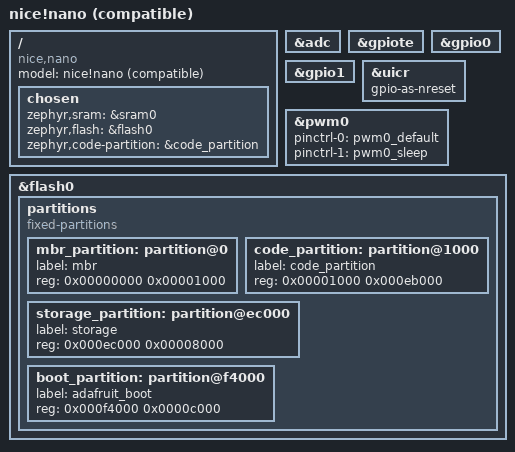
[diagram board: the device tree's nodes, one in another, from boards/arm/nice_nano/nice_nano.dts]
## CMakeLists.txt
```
cmake_minimum_required(VERSION 3.20.0)

# Pick up the local board definition under boards/arm/nice_nano/
list(APPEND BOARD_ROOT ${CMAKE_CURRENT_SOURCE_DIR})

find_package(Zephyr REQUIRED HINTS $ENV{ZEPHYR_BASE})
project(irtransmitter)

target_sources(app PRIVATE
    src/main.c
    src/ir.c
    src/ir_rx.c
    src/crashlog.c
)

target_include_directories(app PRIVATE src)
```

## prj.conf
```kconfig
# BLE peripheral with Nordic UART Service
# Off while learning codes: the capture ISR polls the pin with IRQs masked.
CONFIG_BT=n
#CONFIG_BT_PERIPHERAL=y
#CONFIG_BT_DEVICE_NAME="IR-Tx"
#CONFIG_BT_MAX_CONN=1
#CONFIG_BT_NUS=y

# Larger MTU so a long IR code fits in one BLE write
#CONFIG_BT_BUF_ACL_RX_SIZE=251
#CONFIG_BT_BUF_ACL_TX_SIZE=251
#CONFIG_BT_L2CAP_TX_MTU=247

# IR carrier hardware
CONFIG_PWM=y
CONFIG_GPIO=y

# USB CDC ACM serial = console + logs + command input (no J-Link needed)
CONFIG_USB_DEVICE_STACK=y
CONFIG_USB_DEVICE_PRODUCT="IR-Tx"
CONFIG_USB_DEVICE_INITIALIZE_AT_BOOT=n
CONFIG_SERIAL=y
CONFIG_UART_INTERRUPT_DRIVEN=y
CONFIG_UART_LINE_CTRL=y
CONFIG_CONSOLE=y
CONFIG_UART_CONSOLE=y

# No logging subsystem: its thread would be another concurrent writer on
# the CDC ACM TX ring buffer. Everything goes through printk on main.
CONFIG_LOG=n
CONFIG_USB_CDC_ACM_RINGBUF_SIZE=4096

# Memory
CONFIG_HEAP_MEM_POOL_SIZE=2048
CONFIG_MAIN_STACK_SIZE=2048

CONFIG_ASSERT=y

# Thread names for the crash log
CONFIG_THREAD_NAME=y
# Our own fatal handler (src/crashlog.c) replaces NCS's
CONFIG_RESET_ON_FATAL_ERROR=n
```

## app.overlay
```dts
/* USB CDC ACM serial port as the console. */
/ {
	chosen {
		zephyr,console = &cdc_acm_uart0;
	};
};

&usbd {
	status = "okay";
	cdc_acm_uart0: cdc_acm_uart0 {
		compatible = "zephyr,cdc-acm-uart";
	};
};
```

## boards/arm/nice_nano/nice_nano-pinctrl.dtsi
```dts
&pinctrl {
	/* IR carrier: PWM0 channel 0 -> P0.31 (DAT of the IR transmitter module). */
	pwm0_default: pwm0_default {
		group1 {
			psels = <NRF_PSEL(PWM_OUT0, 0, 31)>;
			/* The module has no transistor: DAT drives the IR LED directly. */
			nordic,drive-mode = <NRF_DRIVE_H0H1>;
		};
	};

	pwm0_sleep: pwm0_sleep {
		group1 {
			psels = <NRF_PSEL(PWM_OUT0, 0, 31)>;
			low-power-enable;
		};
	};
};
```

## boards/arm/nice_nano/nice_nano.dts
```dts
/dts-v1/;
#include <nordic/nrf52840_qiaa.dtsi>
#include "nice_nano-pinctrl.dtsi"

/ {
	model = "nice!nano (compatible)";
	compatible = "nice,nano";

	chosen {
		zephyr,sram = &sram0;
		zephyr,flash = &flash0;
		zephyr,code-partition = &code_partition;
	};
};

&adc {
	status = "okay";
};

&gpiote {
	status = "okay";
};

&gpio0 {
	status = "okay";
};

&gpio1 {
	status = "okay";
};

&uicr {
	gpio-as-nreset;
};

&pwm0 {
	status = "okay";
	pinctrl-0 = <&pwm0_default>;
	pinctrl-1 = <&pwm0_sleep>;
	pinctrl-names = "default", "sleep";
};

&flash0 {
	/*
	 * Layout for the Adafruit nRF52 bootloader with NO SoftDevice
	 * (INFO_UF2.TXT: "SoftDevice: not found"): the bootloader then jumps
	 * to MBR_SIZE = 0x1000. Bootloader occupies the last 48 KB of flash.
	 */
	partitions {
		compatible = "fixed-partitions";
		#address-cells = <1>;
		#size-cells = <1>;

		mbr_partition: partition@0 {
			label = "mbr";
			reg = <0x00000000 0x00001000>;
		};

		code_partition: partition@1000 {
			label = "code_partition";
			reg = <0x00001000 0x000eb000>;
		};

		storage_partition: partition@ec000 {
			label = "storage";
			reg = <0x000ec000 0x00008000>;
		};

		boot_partition: partition@f4000 {
			label = "adafruit_boot";
			reg = <0x000f4000 0x0000c000>;
		};
	};
};
```

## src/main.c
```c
#include <stdio.h>
#include <stdlib.h>
#include <string.h>

#include <soc.h>
#include <zephyr/kernel.h>
#include <zephyr/sys/printk.h>
#include <zephyr/logging/log.h>
#include <zephyr/drivers/uart.h>
#include <zephyr/drivers/pwm.h>
#include <zephyr/drivers/gpio.h>
#include <zephyr/dt-bindings/gpio/nordic-nrf-gpio.h>
#include <zephyr/usb/usb_device.h>
#if defined(CONFIG_BT)
#include <zephyr/bluetooth/bluetooth.h>
#include <zephyr/bluetooth/conn.h>
#include <zephyr/bluetooth/uuid.h>
#include <bluetooth/services/nus.h>
#endif

#include "ir.h"
#include "ir_rx.h"

void crashlog_boot(void);
void crashlog_report(void);

LOG_MODULE_REGISTER(main, LOG_LEVEL_INF);

#define LINE_BUF_SIZE 4096
#define MAX_PULSES    1024

/* Shortest frame worth reporting (leader + a few bits). */
#define MIN_FRAME_DURATIONS 8

/*
 * nice!nano switched VCC pin (feeds the IR transmitter module): P0.13
 * drives the switch. Active low on v2, active high on v1; EXTVCC overrides.
 */
#define EXT_VCC_PIN     13
#define EXT_VCC_ON_LEVEL 0

/* Samsung32 timings (us) and the TV's address byte. */
#define SAMSUNG_ADDR    0x07
#define SAMSUNG_HDR     4500
#define SAMSUNG_BIT     560
#define SAMSUNG_ONE     1690
#define SAMSUNG_ZERO    560
#define SAMSUNG_GAP     46000

/* Adafruit nRF52 bootloader: GPREGRET magic that reboots into UF2 mode. */
#define DFU_MAGIC_UF2_RESET 0x57

typedef void (*reply_fn)(const char *msg);

static uint16_t pulse_buf[MAX_PULSES];

/* Last captured frame, replayed by REPLAY. */
static uint16_t last_rx[IR_RX_MAX_PULSES];
static size_t   last_rx_len;

/* Commands arrive from both USB console and BLE NUS threads. */
static K_MUTEX_DEFINE(cmd_lock);

#if defined(CONFIG_BT)
static char     line_buf[LINE_BUF_SIZE];
static size_t   line_len;

static struct bt_conn *current_conn;

static const struct bt_data ad[] = {
	BT_DATA_BYTES(BT_DATA_FLAGS, (BT_LE_AD_GENERAL | BT_LE_AD_NO_BREDR)),
	BT_DATA(BT_DATA_NAME_COMPLETE, CONFIG_BT_DEVICE_NAME,
		sizeof(CONFIG_BT_DEVICE_NAME) - 1),
};

static const struct bt_data sd[] = {
	BT_DATA_BYTES(BT_DATA_UUID128_ALL, BT_UUID_NUS_VAL),
};

static void nus_reply(const char *msg)
{
	if (!current_conn) {
		return;
	}
	int err = bt_nus_send(current_conn, (const uint8_t *)msg, strlen(msg));
	if (err) {
		LOG_WRN("nus send failed: %d", err);
	}
}

#endif /* CONFIG_BT */

static void usb_reply(const char *msg)
{
	printk("%s", msg);
}

static void send_and_reply(uint32_t carrier_hz, const uint16_t *d, size_t n,
			   reply_fn reply)
{
	int err = ir_send_raw(carrier_hz, d, n);
	if (err) {
		char buf[32];
		snprintf(buf, sizeof(buf), "ERR send %d\n", err);
		reply(buf);
	} else {
		reply("OK\n");
	}
}

/* Samsung32: addr, addr, cmd, ~cmd, LSB first, then a stop bit. Returns durations. */
static size_t samsung_frame(uint8_t cmd, uint16_t *d)
{
	uint32_t v = SAMSUNG_ADDR | (SAMSUNG_ADDR << 8) | ((uint32_t)cmd << 16) |
		     ((uint32_t)(uint8_t)~cmd << 24);
	size_t n = 0;

	d[n++] = SAMSUNG_HDR;
	d[n++] = SAMSUNG_HDR;
	for (int i = 0; i < 32; i++) {
		d[n++] = SAMSUNG_BIT;
		d[n++] = (v & BIT(i)) ? SAMSUNG_ONE : SAMSUNG_ZERO;
	}
	d[n++] = SAMSUNG_BIT;
	d[n++] = SAMSUNG_GAP;
	return n;
}

static void print_frame(const uint16_t *d, size_t n, bool raw);

/*
 * Connect the input buffer (with pull-up, so idle pins stay high) on every
 * pin not used by the firmware, so pin scans can see a stray wire.
 * Returns the mask of P0 pins that were left alone.
 */
static uint32_t scan_inputs_enable(void)
{
	/* Skip: P0.13 ext VCC, P0.15 LED, P0.17 RX power, P0.18 reset, P0.20 RX, P0.31 IR TX. */
	const uint32_t skip0 = BIT(13) | BIT(15) | BIT(17) | BIT(18) | BIT(20) | BIT(31);

	for (int p = 0; p < 48; p++) {
		if (p < 32 && (skip0 & BIT(p))) {
			continue;
		}
		volatile uint32_t *cnf = p < 32 ? &NRF_P0->PIN_CNF[p] : &NRF_P1->PIN_CNF[p - 32];

		*cnf = GPIO_PIN_CNF_DIR_Input << GPIO_PIN_CNF_DIR_Pos |
		       GPIO_PIN_CNF_INPUT_Connect << GPIO_PIN_CNF_INPUT_Pos |
		       GPIO_PIN_CNF_PULL_Pullup << GPIO_PIN_CNF_PULL_Pos;
	}
	k_msleep(5);
	return skip0 & ~BIT(20);
}

/* IR LED pin, for the bit-banged carrier diagnostic (PWM must be idle). */
#define IR_TX_PIN 31

/* Bit-banged 38 kHz carrier at 1/3 duty, sampling our receiver meanwhile. */
static void bitbang_send(const uint16_t *d, size_t n)
{
	const uint32_t cpu = SystemCoreClock / 1000000U;
	const uint32_t period = SystemCoreClock / 38000U;
	const uint32_t high = period / 3U;

	for (size_t i = 0; i < n; i++) {
		uint32_t start = DWT->CYCCNT;
		uint32_t span = d[i] * cpu;
		bool mark = (i & 1U) == 0U;

		while (DWT->CYCCNT - start < span) {
			if (mark && (DWT->CYCCNT - start) % period < high) {
				NRF_P0->OUTSET = BIT(IR_TX_PIN);
			} else {
				NRF_P0->OUTCLR = BIT(IR_TX_PIN);
			}
			ir_rx_loopback_sample();
		}
	}
	NRF_P0->OUTCLR = BIT(IR_TX_PIN);
}

static void process_line(char *line, reply_fn reply)
{
	char *saveptr = NULL;
	char *cmd = strtok_r(line, " ", &saveptr);
	if (!cmd) {
		reply("ERR empty\n");
		return;
	}

	if (strcmp(cmd, "TX") == 0) {
		char *khz_str = strtok_r(NULL, " ", &saveptr);
		if (!khz_str) {
			reply("ERR no_khz\n");
			return;
		}
		int khz = atoi(khz_str);
		if (khz < 20 || khz > 60) {
			reply("ERR bad_khz\n");
			return;
		}

		size_t n = 0;
		char *tok;
		while ((tok = strtok_r(NULL, " ", &saveptr)) != NULL) {
			if (n >= MAX_PULSES) {
				reply("ERR too_many\n");
				return;
			}
			int v = atoi(tok);
			if (v <= 0 || v > 65535) {
				reply("ERR bad_pulse\n");
				return;
			}
			pulse_buf[n++] = (uint16_t)v;
		}
		if (n < 2) {
			reply("ERR no_pulses\n");
			return;
		}
		if (n & 1U) {
			reply("ERR odd_pulses\n");
			return;
		}

		send_and_reply((uint32_t)khz * 1000U, pulse_buf, n, reply);
	} else if (strcmp(cmd, "REPLAY") == 0) {
		char *khz_str = strtok_r(NULL, " ", &saveptr);
		int khz = khz_str ? atoi(khz_str) : 38;

		if (last_rx_len < 2) {
			reply("ERR nothing_captured\n");
			return;
		}
		send_and_reply((uint32_t)khz * 1000U, last_rx, last_rx_len, reply);
	} else if (strcmp(cmd, "SAMSUNG") == 0) {
		char *arg = strtok_r(NULL, " ", &saveptr);
		char *rep = strtok_r(NULL, " ", &saveptr);
		int times = rep ? atoi(rep) : 1;

		if (!arg) {
			reply("ERR no_cmd\n");
			return;
		}
		size_t n = samsung_frame((uint8_t)strtoul(arg, NULL, 0), pulse_buf);
		for (int i = 0; i < times; i++) {
			int err = ir_send_raw(38000U, pulse_buf, n);
			if (err) {
				char buf[32];
				snprintf(buf, sizeof(buf), "ERR send %d\n", err);
				reply(buf);
				return;
			}
		}
		reply("OK\n");
	} else if (strcmp(cmd, "LOOP") == 0) {
		/* Send a Samsung frame and decode what our own receiver saw. */
		static uint16_t rx[IR_RX_MAX_PULSES];
		char *arg = strtok_r(NULL, " ", &saveptr);
		bool raw;

		if (!arg) {
			reply("ERR no_cmd\n");
			return;
		}
		size_t n = samsung_frame((uint8_t)strtoul(arg, NULL, 0), pulse_buf);

		ir_rx_loopback_begin();
		int err = ir_send_raw_ex(38000U, pulse_buf, n, ir_rx_loopback_wait_us);
		size_t got = ir_rx_loopback_end(rx, ARRAY_SIZE(rx), &raw);

		if (err) {
			reply("ERR send\n");
		} else if (got == 0) {
			reply("LOOP nothing received\n");
		} else {
			print_frame(rx, got, raw);
		}
	} else if (strcmp(cmd, "LOOPBB") == 0) {
		/* Like LOOP but with a CPU bit-banged carrier: isolates the PWM. */
		static uint16_t rx[IR_RX_MAX_PULSES];
		char *arg = strtok_r(NULL, " ", &saveptr);
		bool raw;

		if (!arg) {
			reply("ERR no_cmd\n");
			return;
		}
		size_t n = samsung_frame((uint8_t)strtoul(arg, NULL, 0), pulse_buf);

		NRF_P0->PIN_CNF[IR_TX_PIN] = GPIO_PIN_CNF_DIR_Output << GPIO_PIN_CNF_DIR_Pos |
					     GPIO_PIN_CNF_INPUT_Disconnect << GPIO_PIN_CNF_INPUT_Pos |
					     GPIO_PIN_CNF_DRIVE_H0H1 << GPIO_PIN_CNF_DRIVE_Pos;
		/* An enabled PWM owns its PSEL pin and would override the GPIO. */
		uint32_t pwm_en = NRF_PWM0->ENABLE;

		NRF_PWM0->ENABLE = 0;
		ir_rx_loopback_begin();
		unsigned int key = irq_lock();
		bitbang_send(pulse_buf, n);
		irq_unlock(key);
		NRF_PWM0->ENABLE = pwm_en;
		size_t got = ir_rx_loopback_end(rx, ARRAY_SIZE(rx), &raw);

		if (got == 0) {
			reply("LOOPBB nothing received\n");
		} else {
			print_frame(rx, got, raw);
		}
	} else if (strcmp(cmd, "TXSCAN") == 0) {
		/* Transmit a Samsung frame while counting transitions on every pin. */
		static uint32_t changes[48];
		static uint32_t prev0, prev1;
		char *arg = strtok_r(NULL, " ", &saveptr);
		size_t n = samsung_frame(arg ? (uint8_t)strtoul(arg, NULL, 0) : 0x07, pulse_buf);
		const uint32_t cpu = SystemCoreClock / 1000000U;

		memset(changes, 0, sizeof(changes));
		scan_inputs_enable();
		gpio_pin_interrupt_configure(DEVICE_DT_GET(DT_NODELABEL(gpio0)), 20, GPIO_INT_DISABLE);
		prev0 = NRF_P0->IN;
		prev1 = NRF_P1->IN;

		uint32_t period_ns = 1000000000U / 38000U;
		const struct device *pwm = DEVICE_DT_GET(DT_NODELABEL(pwm0));

		for (size_t i = 0; i <= n; i++) {
			/* One extra round after the frame: listen for the receiver's tail. */
			uint32_t dur = i < n ? pulse_buf[i] : 20000U;
			bool mark = i < n && (i & 1U) == 0U;

			pwm_set(pwm, 0, period_ns, mark ? period_ns / 3U : 0U, 0);
			uint32_t start = DWT->CYCCNT;

			while (DWT->CYCCNT - start < dur * cpu) {
				uint32_t in0 = NRF_P0->IN, in1 = NRF_P1->IN;
				uint32_t d0 = (in0 ^ prev0) & ~BIT(31), d1 = in1 ^ prev1;

				while (d0) {
					changes[__builtin_ctz(d0)]++;
					d0 &= d0 - 1;
				}
				while (d1) {
					changes[32 + __builtin_ctz(d1)]++;
					d1 &= d1 - 1;
				}
				prev0 = in0;
				prev1 = in1;
			}
		}
		gpio_pin_interrupt_configure(DEVICE_DT_GET(DT_NODELABEL(gpio0)), 20, GPIO_INT_EDGE_FALLING);

		printk("TXSCAN P0.IN=0x%08X P1.IN=0x%08X changes:", prev0, prev1);
		for (int p = 0; p < 48; p++) {
			if (changes[p]) {
				printk(" P%d.%02d=%u", p / 32, p % 32, changes[p]);
			}
		}
		printk(" (end)\n");
	} else if (strcmp(cmd, "SCAN") == 0) {
		/*
		 * Find which pin a signal actually arrives on: connect the input
		 * buffer (with pull-up, so idle pins stay high) on every free pin,
		 * poll both ports and count transitions per pin.
		 */
		char *arg = strtok_r(NULL, " ", &saveptr);
		uint32_t secs = arg ? strtoul(arg, NULL, 0) : 15;
		static uint32_t changes[48];
		const uint32_t skip0 = scan_inputs_enable();

		memset(changes, 0, sizeof(changes));

		printk("SCAN %us: press the remote now\n", secs);
		uint32_t prev0 = NRF_P0->IN, prev1 = NRF_P1->IN;
		int64_t end = k_uptime_get() + secs * 1000;

		while (k_uptime_get() < end) {
			uint32_t in0 = NRF_P0->IN, in1 = NRF_P1->IN;
			uint32_t d0 = (in0 ^ prev0) & ~skip0, d1 = in1 ^ prev1;

			while (d0) {
				int b = __builtin_ctz(d0);
				changes[b]++;
				d0 &= d0 - 1;
			}
			while (d1) {
				int b = __builtin_ctz(d1);
				changes[32 + b]++;
				d1 &= d1 - 1;
			}
			prev0 = in0;
			prev1 = in1;
		}

		printk("SCAN result:");
		for (int p = 0; p < 48; p++) {
			if (changes[p]) {
				printk(" P%d.%02d=%u", p / 32, p % 32, changes[p]);
			}
		}
		printk(" (end)\n");
	} else if (strcmp(cmd, "PROBE") == 0) {
		char buf[48];

		snprintf(buf, sizeof(buf), "PROBE out_with_pulldown=%d\n", ir_rx_probe());
		reply(buf);
	} else if (strcmp(cmd, "REGS") == 0) {
		char buf[160];

		snprintf(buf, sizeof(buf),
			 "REGS PWM0.ENABLE=%u PWM0.PSEL0=0x%08X PIN_CNF31=0x%08X OUT31=%u P0.13=%u\n",
			 NRF_PWM0->ENABLE, NRF_PWM0->PSEL.OUT[0], NRF_P0->PIN_CNF[IR_TX_PIN],
			 (NRF_P0->OUT >> IR_TX_PIN) & 1U, (NRF_P0->OUT >> 13) & 1U);
		reply(buf);
	} else if (strcmp(cmd, "PINTEST") == 0) {
		/*
		 * Drive P0.31 as plain GPIO (PWM released) and read back the real
		 * pin level through the input buffer: catches shorts, and blinks
		 * the module's LED without relying on the PWM driver.
		 */
		char *arg = strtok_r(NULL, " ", &saveptr);
		int times = arg ? atoi(arg) : 5;
		uint32_t pwm_en = NRF_PWM0->ENABLE;
		char buf[64];

		NRF_PWM0->ENABLE = 0;
		NRF_P0->PIN_CNF[IR_TX_PIN] = GPIO_PIN_CNF_DIR_Output << GPIO_PIN_CNF_DIR_Pos |
					     GPIO_PIN_CNF_INPUT_Connect << GPIO_PIN_CNF_INPUT_Pos |
					     GPIO_PIN_CNF_DRIVE_H0H1 << GPIO_PIN_CNF_DRIVE_Pos;
		for (int i = 0; i < times; i++) {
			NRF_P0->OUTSET = BIT(IR_TX_PIN);
			k_msleep(1000);
			int hi = (NRF_P0->IN >> IR_TX_PIN) & 1U;
			NRF_P0->OUTCLR = BIT(IR_TX_PIN);
			k_msleep(1000);
			int lo = (NRF_P0->IN >> IR_TX_PIN) & 1U;

			snprintf(buf, sizeof(buf), "PINTEST %d: wrote 1 read %d, wrote 0 read %d\n",
				 i + 1, hi, lo);
			reply(buf);
		}
		NRF_PWM0->ENABLE = pwm_en;
	} else if (strcmp(cmd, "SLOWBLINK") == 0) {
		char *arg = strtok_r(NULL, " ", &saveptr);
		int times = arg ? atoi(arg) : 10;

		for (int i = 0; i < times; i++) {
			ir_level(true);
			k_msleep(1000);
			ir_level(false);
			k_msleep(1000);
		}
		reply("OK\n");
	} else if (strcmp(cmd, "BLINK") == 0) {
		/* Visible through a phone camera: 5 x 0.5 s bursts of carrier. */
		ir_pulse(500, 500, 5);
		reply("OK\n");
	} else if (strcmp(cmd, "PWR29") == 0) {
		/* Power the transmitter module from P0.29 (high drive) instead of VCC. */
		char *arg = strtok_r(NULL, " ", &saveptr);
		int on = arg ? atoi(arg) : 1;

		gpio_pin_configure(DEVICE_DT_GET(DT_NODELABEL(gpio0)), 29,
				   (on ? GPIO_OUTPUT_HIGH : GPIO_OUTPUT_LOW) | NRF_GPIO_DRIVE_H0H1);
		reply("OK\n");
	} else if (strcmp(cmd, "INV") == 0) {
		char *arg = strtok_r(NULL, " ", &saveptr);

		ir_set_inverted(arg && atoi(arg));
		reply("OK\n");
	} else if (strcmp(cmd, "EXTVCC") == 0) {
		char *arg = strtok_r(NULL, " ", &saveptr);
		int on = arg ? atoi(arg) : 1;

		gpio_pin_set_raw(DEVICE_DT_GET(DT_NODELABEL(gpio0)), EXT_VCC_PIN,
				 on ? EXT_VCC_ON_LEVEL : !EXT_VCC_ON_LEVEL);
		reply("OK\n");
	} else if (strcmp(cmd, "STAT") == 0) {
		int pwr, out;
		uint32_t edges;
		char buf[64];

		ir_rx_stat(&pwr, &out, &edges);
		snprintf(buf, sizeof(buf), "STAT pwr=%d out=%d edges=%u\n", pwr, out, edges);
		reply(buf);
	} else if (strcmp(cmd, "CRASH") == 0) {
		crashlog_report();
	} else if (strcmp(cmd, "DUMP") == 0) {
		const uint16_t *iv;
		size_t n = ir_rx_last_raw(&iv);

		printk("DUMP %u", (unsigned)n);
		for (size_t i = 0; i < n; i++) {
			printk(" %u", iv[i]);
		}
		printk("\n");
	} else if (strcmp(cmd, "DFU") == 0) {
		reply("OK rebooting to UF2 bootloader\n");
		k_msleep(100);
		NRF_POWER->GPREGRET = DFU_MAGIC_UF2_RESET;
		NVIC_SystemReset();
	} else {
		reply("ERR unknown\n");
	}
}

#if defined(CONFIG_BT)
static void nus_received(struct bt_conn *conn, const uint8_t *const data,
			 uint16_t len)
{
	ARG_UNUSED(conn);

	for (uint16_t i = 0; i < len; i++) {
		char c = (char)data[i];
		if (c == '\n' || c == '\r') {
			if (line_len > 0) {
				line_buf[line_len] = '\0';
				k_mutex_lock(&cmd_lock, K_FOREVER);
				process_line(line_buf, nus_reply);
				k_mutex_unlock(&cmd_lock);
				line_len = 0;
			}
		} else if (line_len < LINE_BUF_SIZE - 1) {
			line_buf[line_len++] = c;
		} else {
			line_len = 0;
			nus_reply("ERR overflow\n");
		}
	}
}

static struct bt_nus_cb nus_cb = {
	.received = nus_received,
};

static void connected(struct bt_conn *conn, uint8_t err)
{
	if (err) {
		LOG_ERR("Connection failed (err %u)", err);
		return;
	}
	current_conn = bt_conn_ref(conn);
	LOG_INF("Connected");
}

static void disconnected(struct bt_conn *conn, uint8_t reason)
{
	ARG_UNUSED(conn);
	LOG_INF("Disconnected (reason %u)", reason);
	line_len = 0;
	if (current_conn) {
		bt_conn_unref(current_conn);
		current_conn = NULL;
	}
}

BT_CONN_CB_DEFINE(conn_callbacks) = {
	.connected    = connected,
	.disconnected = disconnected,
};

#endif /* CONFIG_BT */

/*
 * USB console input, polled from the main loop. All console output also
 * happens on the main thread: the CDC ACM TX ring buffer is not safe with
 * several concurrent producers (that race crashed the board).
 */
static const struct device *const console_uart = DEVICE_DT_GET(DT_CHOSEN(zephyr_console));
static char   console_buf[LINE_BUF_SIZE];
static size_t console_len;

static void poll_console(void)
{
	unsigned char c;

	while (uart_poll_in(console_uart, &c) == 0) {
		if (c == '\r' || c == '\n') {
			if (console_len > 0) {
				console_buf[console_len] = '\0';
				k_mutex_lock(&cmd_lock, K_FOREVER);
				process_line(console_buf, usb_reply);
				k_mutex_unlock(&cmd_lock);
				console_len = 0;
			}
		} else if (console_len < LINE_BUF_SIZE - 1) {
			console_buf[console_len++] = (char)c;
		} else {
			console_len = 0;
			usb_reply("ERR overflow\n");
		}
	}
}

static void print_frame(const uint16_t *d, size_t n, bool raw)
{
	char desc[96];

	ir_rx_describe(d, n, desc, sizeof(desc));
	printk("\n[IR] %s%s\n", desc, raw ? " [sw-demod]" : "");
	printk("TX 38");
	for (size_t i = 0; i < n; i++) {
		printk(" %u", d[i]);
	}
	printk("\n");
}

int main(void)
{
	int err;

	crashlog_boot();

	/* Blue LED on P0.15 = firmware is running. */
	gpio_pin_configure(DEVICE_DT_GET(DT_NODELABEL(gpio0)), 15, GPIO_OUTPUT_HIGH);

	/* Switched VCC on, for the IR transmitter module. */
	gpio_pin_configure(DEVICE_DT_GET(DT_NODELABEL(gpio0)), EXT_VCC_PIN,
			   EXT_VCC_ON_LEVEL ? GPIO_OUTPUT_HIGH : GPIO_OUTPUT_LOW);

	err = usb_enable(NULL);
	if (err) {
		LOG_ERR("USB enable failed: %d", err);
	}

	err = ir_init();
	if (err) {
		LOG_ERR("IR init failed: %d", err);
		return 0;
	}

	err = ir_rx_init();
	if (err) {
		LOG_ERR("IR RX init failed: %d", err);
		return 0;
	}

#if defined(CONFIG_BT)
	err = bt_enable(NULL);
	if (err) {
		LOG_ERR("BT enable failed: %d", err);
	} else if ((err = bt_nus_init(&nus_cb)) != 0) {
		LOG_ERR("NUS init failed: %d", err);
	} else if ((err = bt_le_adv_start(BT_LE_ADV_CONN, ad, ARRAY_SIZE(ad),
					  sd, ARRAY_SIZE(sd))) != 0) {
		LOG_ERR("Advertising start failed: %d", err);
	}
#endif

	printk("IR-Tx ready: point the remote at the receiver. Commands: REPLAY [khz] | TX khz d0 d1 ... | SAMSUNG cmd [n] | LOOP cmd | LOOPBB cmd | REGS | PROBE | SCAN [s] | TXSCAN [cmd] | BLINK | SLOWBLINK [n]  PWR29 0/1 | INV 0/1 | EXTVCC 0/1 | STAT | DUMP | CRASH | DFU\n");

	static uint16_t frame[IR_RX_MAX_PULSES];

	for (;;) {
		bool raw;
		size_t n = ir_rx_poll(frame, ARRAY_SIZE(frame), &raw);
		/* A real frame has a leader plus data; shorter bursts are glitches. */
		if (n >= MIN_FRAME_DURATIONS) {
			k_mutex_lock(&cmd_lock, K_FOREVER);
			memcpy(last_rx, frame, n * sizeof(frame[0]));
			last_rx_len = n;
			k_mutex_unlock(&cmd_lock);
			print_frame(frame, n, raw);
		}
		poll_console();
		k_msleep(5);
	}

	return 0;
}
```

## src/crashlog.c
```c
/*
 * Crash "black box": the fatal error handler stores reason and faulting PC
 * in RAM that survives a soft reset, so it can be reported on the next boot
 * over USB (no J-Link on this board).
 */
#include <soc.h>
#include <zephyr/kernel.h>
#include <zephyr/arch/cpu.h>
#include <zephyr/fatal.h>
#include <zephyr/linker/section_tags.h>
#include <zephyr/sys/printk.h>
#include <string.h>

#define CRASH_MAGIC 0xC0FFEE42U

struct crash_info {
	uint32_t magic;
	uint32_t reason;
	uint32_t pc;
	uint32_t lr;
	char     thread[16];
};

static __noinit struct crash_info crash;
static uint32_t boot_resetreas;

void k_sys_fatal_error_handler(unsigned int reason, const z_arch_esf_t *esf)
{
	const char *name = k_thread_name_get(k_current_get());

	crash.magic = CRASH_MAGIC;
	crash.reason = reason;
	crash.pc = esf ? esf->basic.pc : 0;
	crash.lr = esf ? esf->basic.lr : 0;
	strncpy(crash.thread, name ? name : "?", sizeof(crash.thread) - 1);
	crash.thread[sizeof(crash.thread) - 1] = '\0';

	NVIC_SystemReset();
	CODE_UNREACHABLE;
}

void crashlog_boot(void)
{
	boot_resetreas = NRF_POWER->RESETREAS;
	NRF_POWER->RESETREAS = boot_resetreas; /* write-1-to-clear */
}

void crashlog_report(void)
{
	printk("RESETREAS=0x%08X", boot_resetreas);
	if (crash.magic == CRASH_MAGIC) {
		printk(" CRASH reason=%u pc=0x%08X lr=0x%08X thread=%s\n",
		       crash.reason, crash.pc, crash.lr, crash.thread);
	} else {
		printk(" no crash recorded\n");
	}
}
```

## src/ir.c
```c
#include "ir.h"

#include <errno.h>
#include <zephyr/kernel.h>
#include <zephyr/device.h>
#include <zephyr/devicetree.h>
#include <zephyr/drivers/pwm.h>
#include <zephyr/logging/log.h>

LOG_MODULE_REGISTER(ir, LOG_LEVEL_INF);

#define IR_PWM_NODE    DT_NODELABEL(pwm0)
#define IR_PWM_CHANNEL 0

static const struct device *const ir_pwm = DEVICE_DT_GET(IR_PWM_NODE);

/* Some transmitter modules light the LED with DAT low: invert the carrier. */
static pwm_flags_t ir_flags;

void ir_set_inverted(bool inverted)
{
	ir_flags = inverted ? PWM_POLARITY_INVERTED : PWM_POLARITY_NORMAL;
	pwm_set(ir_pwm, IR_PWM_CHANNEL, PWM_USEC(26), 0, ir_flags);
}

int ir_init(void)
{
	if (!device_is_ready(ir_pwm)) {
		LOG_ERR("PWM device not ready");
		return -ENODEV;
	}
	pwm_set(ir_pwm, IR_PWM_CHANNEL, PWM_USEC(26), 0, ir_flags);
	return 0;
}

static void busy_wait_us(uint32_t us)
{
	k_busy_wait(us);
}

int ir_send_raw(uint32_t carrier_hz, const uint16_t *durations_us, size_t count)
{
	return ir_send_raw_ex(carrier_hz, durations_us, count, busy_wait_us);
}

int ir_send_raw_ex(uint32_t carrier_hz, const uint16_t *durations_us,
		   size_t count, void (*wait_us)(uint32_t us))
{
	if (carrier_hz < 20000U || carrier_hz > 60000U) {
		return -EINVAL;
	}
	if (!durations_us || count < 2U || (count & 1U)) {
		return -EINVAL;
	}

	uint32_t period_ns = 1000000000U / carrier_hz;
	uint32_t pulse_ns  = period_ns / 3U;  /* ~33% duty: better current ratio for IR LED */

	for (size_t i = 0; i < count; i++) {
		bool mark = ((i & 1U) == 0U);
		int err = pwm_set(ir_pwm, IR_PWM_CHANNEL, period_ns,
				  mark ? pulse_ns : 0U, ir_flags);
		if (err) {
			LOG_ERR("pwm_set failed at idx %u: %d", (unsigned)i, err);
			pwm_set(ir_pwm, IR_PWM_CHANNEL, period_ns, 0U, ir_flags);
			return err;
		}
		wait_us(durations_us[i]);
	}

	pwm_set(ir_pwm, IR_PWM_CHANNEL, period_ns, 0U, ir_flags);
	return 0;
}

void ir_pulse(uint32_t on_ms, uint32_t off_ms, uint32_t count)
{
	const uint32_t period_ns = PWM_USEC(26);
	const uint32_t pulse_ns  = period_ns / 3U;

	for (uint32_t i = 0; i < count; i++) {
		pwm_set(ir_pwm, IR_PWM_CHANNEL, period_ns, pulse_ns, ir_flags);
		k_msleep(on_ms);
		pwm_set(ir_pwm, IR_PWM_CHANNEL, period_ns, 0U, ir_flags);
		k_msleep(off_ms);
	}
}

void ir_level(bool high)
{
	const uint32_t period_ns = PWM_USEC(26);

	/* 100% duty = DAT steady high, 0% = steady low (no carrier). */
	pwm_set(ir_pwm, IR_PWM_CHANNEL, period_ns, high ? period_ns : 0U, ir_flags);
}
```

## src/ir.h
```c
#ifndef IR_H_
#define IR_H_

#include <stdbool.h>
#include <stddef.h>
#include <stdint.h>

int ir_init(void);

/* Invert the carrier for modules whose LED is on while DAT is low. */
void ir_set_inverted(bool inverted);

/*
 * Send a raw IR sequence.
 *
 * durations_us[0,2,4,...] are mark (carrier on) times in microseconds.
 * durations_us[1,3,5,...] are space (carrier off) times in microseconds.
 * count must be even and >= 2.
 *
 * Blocks until the sequence has been transmitted.
 */
int ir_send_raw(uint32_t carrier_hz, const uint16_t *durations_us, size_t count);

/* Same, with a custom wait for each duration (used by the loopback test). */
int ir_send_raw_ex(uint32_t carrier_hz, const uint16_t *durations_us,
		   size_t count, void (*wait_us)(uint32_t us));

/*
 * Visual heartbeat: pulse the IR LED on/off `count` times so the user can
 * see the board is alive by pointing a phone camera at the LED. Most phone
 * cameras render IR as a faint white/violet glow.
 */
void ir_pulse(uint32_t on_ms, uint32_t off_ms, uint32_t count);

/* Hold DAT steady high or low (diagnostics: visible on the module's LED). */
void ir_level(bool high);

#endif /* IR_H_ */
```

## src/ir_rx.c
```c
#include "ir_rx.h"

#include <errno.h>
#include <stdio.h>
#include <soc.h>
#include <zephyr/kernel.h>
#include <zephyr/device.h>
#include <zephyr/drivers/gpio.h>
#include <zephyr/dt-bindings/gpio/nordic-nrf-gpio.h>
#include <zephyr/logging/log.h>

LOG_MODULE_REGISTER(ir_rx, LOG_LEVEL_INF);

/* IR receiver module (VS1838B / TSOP-style): GND, VCC, OUT. */
#define RX_PWR_PIN 17 /* P0.17 driven high = receiver VCC */
#define RX_OUT_PIN 20 /* P0.20 = demodulated output, active low */

/* Silence longer than this closes a frame (NEC repeats come ~40 ms later). */
#define IR_RX_GAP_US 20000U

#define CYC_PER_US (SystemCoreClock / 1000000U)

static const struct device *const gpio0 = DEVICE_DT_GET(DT_NODELABEL(gpio0));
static struct gpio_callback rx_cb;

/*
 * Edge timestamps (cycle counter), double-buffered: the ISR fills the
 * active buffer while ir_rx_poll() processes the other one.
 */
#define MAX_EDGES 4096

/* Raw (non-demodulating) sensors toggle at the carrier: intervals this short mean "carrier". */
#define CARRIER_MAX_US 150U
/* In raw mode, a pause longer than this ends a mark. */
#define MARK_GAP_US    300U

/* Hard cap on one capture, so a stuck-low input can't hang the CPU. */
#define CAPTURE_MAX_US 300000U

static uint32_t          edges[2][MAX_EDGES];
static uint8_t           active;
static volatile size_t   ready_count;
static volatile bool     ready;
static volatile uint32_t total_edges;

/* Raw edge intervals of the last frame, for DUMP. */
static uint16_t last_iv[MAX_EDGES];
static size_t   last_iv_len;

static inline uint32_t rx_level(void)
{
	return (NRF_P0->IN >> RX_OUT_PIN) & 1U;
}

static volatile uint32_t trigger_cyc;
static K_SEM_DEFINE(trigger_sem, 0, 1);

/* First falling edge of a frame: timestamp it and hand over to the capture thread. */
static void rx_edge(const struct device *dev, struct gpio_callback *cb,
		    uint32_t pins)
{
	ARG_UNUSED(cb);
	ARG_UNUSED(pins);

	trigger_cyc = DWT->CYCCNT;
	gpio_pin_interrupt_configure(dev, RX_OUT_PIN, GPIO_INT_DISABLE);
	k_sem_give(&trigger_sem);
}

/*
 * Polls the pin in a tight loop (sub-microsecond resolution) until the
 * line has been quiet for IR_RX_GAP_US. Runs as a cooperative thread with
 * interrupts enabled, so USB keeps being serviced; an ISR only adds a few
 * microseconds of jitter. One interrupt per edge can't keep up with
 * sensors that output the carrier itself.
 */
static void capture_thread(void)
{
	const uint32_t gap = IR_RX_GAP_US * CYC_PER_US;
	const uint32_t cap = CAPTURE_MAX_US * CYC_PER_US;

	for (;;) {
		k_sem_take(&trigger_sem, K_FOREVER);

		uint32_t *e = edges[active];
		size_t m = 0;
		uint32_t t0 = trigger_cyc;
		uint32_t last = DWT->CYCCNT;
		uint32_t level = rx_level();

		/* The triggering edge went low; if we're already high again, that mark ended too. */
		e[m++] = t0;
		if (level != 0U) {
			e[m++] = last;
		}

		for (;;) {
			uint32_t now = DWT->CYCCNT;
			uint32_t l = rx_level();

			if (l != level) {
				level = l;
				if (m < MAX_EDGES) {
					e[m++] = now;
				}
				last = now;
			} else if (now - last > gap || now - t0 > cap) {
				break;
			}
		}

		total_edges += m;
		if (m >= 2 && !ready) {
			ready_count = m;
			ready = true;
		}

		/*
		 * This is the highest-priority thread and it busy-polls: give the
		 * rest of the system (console, USB) time to run before re-arming,
		 * otherwise a noisy line would starve everything else.
		 */
		k_msleep(10);
		gpio_pin_interrupt_configure(gpio0, RX_OUT_PIN, GPIO_INT_EDGE_FALLING);
	}
}

K_THREAD_DEFINE(ir_capture_tid, 1024, capture_thread, NULL, NULL, NULL,
		K_PRIO_COOP(0), 0, 0);

int ir_rx_init(void)
{
	int err;

	if (!device_is_ready(gpio0)) {
		return -ENODEV;
	}

	/* Cycle counter at core clock (64 MHz) for microsecond timestamps. */
	CoreDebug->DEMCR |= CoreDebug_DEMCR_TRCENA_Msk;
	DWT->CYCCNT = 0;
	DWT->CTRL |= DWT_CTRL_CYCCNTENA_Msk;

	err = gpio_pin_configure(gpio0, RX_PWR_PIN,
				 GPIO_OUTPUT_HIGH | NRF_GPIO_DRIVE_H0H1);
	if (err) {
		return err;
	}

	err = gpio_pin_configure(gpio0, RX_OUT_PIN, GPIO_INPUT | GPIO_PULL_UP);
	if (err) {
		return err;
	}

	gpio_init_callback(&rx_cb, rx_edge, BIT(RX_OUT_PIN));
	err = gpio_add_callback(gpio0, &rx_cb);
	if (err) {
		return err;
	}

	return gpio_pin_interrupt_configure(gpio0, RX_OUT_PIN, GPIO_INT_EDGE_FALLING);
}

static uint16_t clamp_us(uint32_t cyc)
{
	uint32_t us = cyc / CYC_PER_US;
	return us > UINT16_MAX ? UINT16_MAX : (uint16_t)us;
}

static size_t process_edges(const uint32_t *t, size_t m, uint16_t *out,
			    size_t max, bool *raw);

size_t ir_rx_poll(uint16_t *out, size_t max, bool *raw)
{
	const uint32_t *t;
	size_t m = 0;
	unsigned int key = irq_lock();

	if (ready) {
		t = edges[active];
		m = ready_count;
		active ^= 1U;
		ready = false;
	}

	irq_unlock(key);

	if (m < 2) {
		return 0;
	}
	return process_edges(t, m, out, max, raw);
}

static size_t process_edges(const uint32_t *t, size_t m, uint16_t *out,
			    size_t max, bool *raw)
{
	size_t n = 0;

	uint32_t min_cyc = UINT32_MAX;
	for (size_t i = 1; i < m; i++) {
		min_cyc = MIN(min_cyc, t[i] - t[i - 1]);
		last_iv[i - 1] = clamp_us(t[i] - t[i - 1]);
	}
	last_iv_len = m - 1;
	*raw = min_cyc / CYC_PER_US < CARRIER_MAX_US;

	if (*raw) {
		/* Software demodulation: merge carrier pulses into marks. */
		uint32_t burst_start = t[0];

		for (size_t i = 1; i < m && n + 2 <= max; i++) {
			uint32_t gap = t[i] - t[i - 1];
			if (gap / CYC_PER_US > MARK_GAP_US) {
				out[n++] = clamp_us(t[i - 1] - burst_start);
				out[n++] = clamp_us(gap);
				burst_start = t[i];
			}
		}
		if (n < max) {
			out[n++] = clamp_us(t[m - 1] - burst_start);
		}
	} else {
		/* Demodulated receiver: every edge-to-edge interval is a mark or a space. */
		for (size_t i = 1; i < m && n < max; i++) {
			out[n++] = clamp_us(t[i] - t[i - 1]);
		}
	}

	/* Frame ends on a mark: close it with the gap so the TX side gets mark/space pairs. */
	if ((n & 1U) && n < max) {
		out[n++] = IR_RX_GAP_US;
	} else if (n & 1U) {
		n--;
	}
	return n;
}

static bool near(uint32_t v, uint32_t target)
{
	return v > target * 3U / 4U && v < target * 5U / 4U;
}

/* Pulse-distance bits (NEC/Samsung): fixed mark, short/long space. LSB first. */
static int decode_pd(const uint16_t *d, size_t n, size_t start, uint32_t mark,
		     uint32_t one_space, uint32_t zero_space, uint32_t *val)
{
	int bits = 0;

	*val = 0;
	for (size_t i = start; i + 1 < n && bits < 32; i += 2) {
		if (!near(d[i], mark)) {
			break;
		}
		if (near(d[i + 1], one_space)) {
			*val |= 1UL << bits;
		} else if (!near(d[i + 1], zero_space)) {
			break;
		}
		bits++;
	}
	return bits;
}

/* Sony SIRC: pulse-width bits, mark 1200 = 1, 600 = 0, space 600. LSB first. */
static int decode_sony(const uint16_t *d, size_t n, uint32_t *val)
{
	int bits = 0;

	*val = 0;
	for (size_t i = 2; i < n && bits < 20; i += 2) {
		if (near(d[i], 1200)) {
			*val |= 1UL << bits;
		} else if (!near(d[i], 600)) {
			break;
		}
		bits++;
	}
	return bits;
}

void ir_rx_describe(const uint16_t *d, size_t n, char *out, size_t len)
{
	uint32_t v;
	int bits;

	if (n >= 4 && near(d[0], 9000) && near(d[1], 2250)) {
		snprintf(out, len, "NEC repeat");
		return;
	}
	if (n >= 66 && near(d[0], 9000) && near(d[1], 4500)) {
		bits = decode_pd(d, n, 2, 560, 1690, 560, &v);
		if (bits == 32) {
			uint8_t a = v, na = v >> 8, c = v >> 16, nc = v >> 24;
			snprintf(out, len, "NEC addr=0x%02X%s cmd=0x%02X%s (0x%08X)",
				 a, (uint8_t)~a == na ? "" : "(ext)",
				 c, (uint8_t)~c == nc ? "" : "(!chk)", v);
			return;
		}
	}
	if (n >= 66 && near(d[0], 4500) && near(d[1], 4500)) {
		bits = decode_pd(d, n, 2, 560, 1690, 560, &v);
		if (bits == 32) {
			snprintf(out, len, "Samsung addr=0x%04X cmd=0x%02X (0x%08X)",
				 v & 0xFFFF, (v >> 16) & 0xFF, v);
			return;
		}
	}
	if (n >= 26 && near(d[0], 2400) && near(d[1], 600)) {
		bits = decode_sony(d, n, &v);
		if (bits == 12 || bits == 15 || bits == 20) {
			snprintf(out, len, "Sony%d cmd=0x%02X dev=0x%X (0x%X)",
				 bits, v & 0x7F, v >> 7, v);
			return;
		}
	}
	snprintf(out, len, "unknown protocol, leader %u/%u us, %u durations",
		 n > 0 ? d[0] : 0, n > 1 ? d[1] : 0, (unsigned)n);
}

void ir_rx_stat(int *pwr, int *out, uint32_t *edges)
{
	*pwr = gpio_pin_get(gpio0, RX_PWR_PIN);
	*out = gpio_pin_get(gpio0, RX_OUT_PIN);
	*edges = total_edges;
}

size_t ir_rx_last_raw(const uint16_t **iv)
{
	*iv = last_iv;
	return last_iv_len;
}

/* Loopback: the transmitter samples our own receiver while it sends. */
static uint32_t *lb_edges;
static size_t    lb_count;
static uint32_t  lb_level;

void ir_rx_loopback_begin(void)
{
	gpio_pin_interrupt_configure(gpio0, RX_OUT_PIN, GPIO_INT_DISABLE);
	lb_edges = edges[active];
	lb_count = 0;
	lb_level = rx_level();
}

void ir_rx_loopback_sample(void)
{
	uint32_t l = rx_level();

	if (l != lb_level) {
		lb_level = l;
		if (lb_count < MAX_EDGES) {
			lb_edges[lb_count++] = DWT->CYCCNT;
		}
	}
}

void ir_rx_loopback_wait_us(uint32_t us)
{
	uint32_t start = DWT->CYCCNT;
	uint32_t span = us * CYC_PER_US;

	while (DWT->CYCCNT - start < span) {
		ir_rx_loopback_sample();
	}
}

size_t ir_rx_loopback_end(uint16_t *out, size_t max, bool *raw)
{
	/* Receivers lag the light by ~100-200 us: keep listening for the tail. */
	ir_rx_loopback_wait_us(IR_RX_GAP_US);
	gpio_pin_interrupt_configure(gpio0, RX_OUT_PIN, GPIO_INT_EDGE_FALLING);
	total_edges += lb_count;
	return lb_count >= 2 ? process_edges(lb_edges, lb_count, out, max, raw) : 0;
}

int ir_rx_probe(void)
{
	/*
	 * With the internal pull-up swapped for a pull-down, the pin only reads
	 * high if a powered receiver is actively holding its output high.
	 */
	int level;

	gpio_pin_interrupt_configure(gpio0, RX_OUT_PIN, GPIO_INT_DISABLE);
	gpio_pin_configure(gpio0, RX_OUT_PIN, GPIO_INPUT | GPIO_PULL_DOWN);
	k_busy_wait(1000);
	level = gpio_pin_get(gpio0, RX_OUT_PIN);
	gpio_pin_configure(gpio0, RX_OUT_PIN, GPIO_INPUT | GPIO_PULL_UP);
	gpio_pin_interrupt_configure(gpio0, RX_OUT_PIN, GPIO_INT_EDGE_FALLING);
	return level;
}
```

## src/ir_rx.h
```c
#ifndef IR_RX_H_
#define IR_RX_H_

#include <stdbool.h>
#include <stddef.h>
#include <stdint.h>

#define IR_RX_MAX_PULSES 512

int ir_rx_init(void);

/*
 * If a complete frame has been captured (no edges for IR_RX_GAP_US),
 * copy it into out[] and return the number of durations (always even:
 * mark, space, mark, space, ..., the trailing space is the gap).
 * Returns 0 if no frame is ready. *raw is set when the sensor output the
 * carrier itself (no demodulator) and the frame was demodulated in software.
 */
size_t ir_rx_poll(uint16_t *out, size_t max, bool *raw);

/* Print a decoded summary (NEC / Samsung / Sony / raw) of a frame. */
void ir_rx_describe(const uint16_t *d, size_t n, char *buf, size_t buflen);

/* Diagnostics: power pin state, OUT level (idle = 1), edges seen since boot. */
void ir_rx_stat(int *pwr, int *out, uint32_t *edges);

/* Raw edge-to-edge intervals (us) of the last frame. */
size_t ir_rx_last_raw(const uint16_t **iv);

/*
 * Loopback test: begin() stops the normal capture, wait_us() is passed to
 * ir_send_raw_ex() and records receiver edges while transmitting, end()
 * returns the received frame like ir_rx_poll().
 */
void ir_rx_loopback_begin(void);
void ir_rx_loopback_wait_us(uint32_t us);
void ir_rx_loopback_sample(void);
size_t ir_rx_loopback_end(uint16_t *out, size_t max, bool *raw);

/* 1 if a powered receiver drives OUT high (pin read with pull-down). */
int ir_rx_probe(void);

#endif /* IR_RX_H_ */
```
